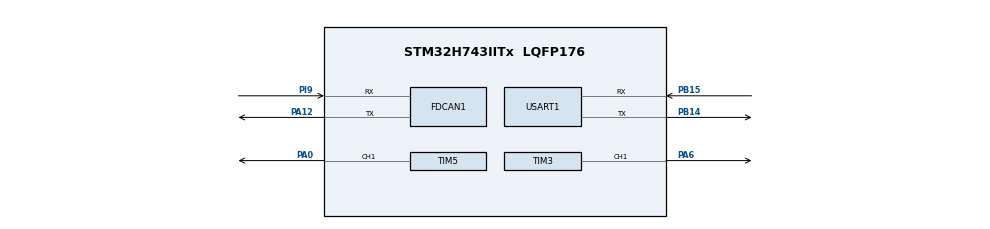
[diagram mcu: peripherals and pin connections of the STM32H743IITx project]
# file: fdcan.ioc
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CORTEX_M7.default_mode_Activation=1
FDCAN1.AutoRetransmission=ENABLE
FDCAN1.CalculateBaudRateNominal=416666
FDCAN1.CalculateTimeBitNominal=2400
FDCAN1.CalculateTimeQuantumNominal=800.0
FDCAN1.DataPrescaler=2
FDCAN1.DataTimeSeg1=7
FDCAN1.DataTimeSeg2=2
Mcu.Family=STM32H7
Mcu.Name=STM32H743IITx
Mcu.Package=LQFP176
NVIC.FDCAN1_IT0_IRQn=true\:0\:0\:false\:false\:true\:true\:true\:true
NVIC.FDCAN1_IT1_IRQn=true\:0\:0\:false\:false\:true\:true\:true\:true
NVIC.PriorityGroup=NVIC_PRIORITYGROUP_4
NVIC.USART1_IRQn=true\:0\:0\:false\:false\:true\:true\:true\:true
PA0.Signal=S_TIM5_CH1
PA12.Mode=FDCAN_Activate
PA12.Signal=FDCAN1_TX
PA6.Signal=S_TIM3_CH1
PB14.Mode=Asynchronous
PB14.Signal=USART1_TX
PB15.Mode=Asynchronous
PB15.Signal=USART1_RX
PH0-OSC_IN\ (PH0).Mode=HSE-External-Oscillator
PH0-OSC_IN\ (PH0).Signal=RCC_OSC_IN
PH1-OSC_OUT\ (PH1).Mode=HSE-External-Oscillator
PH1-OSC_OUT\ (PH1).Signal=RCC_OSC_OUT
PI9.Mode=FDCAN_Activate
PI9.Signal=FDCAN1_RX
ProjectManager.HeapSize=0x200
ProjectManager.StackSize=0x400
ProjectManager.TargetToolchain=MDK-ARM V5
RCC.ADCFreq_Value=400000000
RCC.APB1Freq_Value=100000000
RCC.APB2Freq_Value=50000000
RCC.APB3Freq_Value=100000000
RCC.APB4Freq_Value=100000000
RCC.CortexFreq_Value=100000000
RCC.D2PPRE2=RCC_APB2_DIV2
RCC.DIVM1=2
RCC.DIVM2=5
RCC.DIVM3=25
RCC.DIVN1=16
RCC.DIVN2=160
RCC.DIVN3=336
RCC.DIVQ1=10
RCC.HCLKFreq_Value=100000000
RCC.PLL2FRACN=0
RCC.PLL3FRACN=0
RCC.PLLFRACN=0
RCC.PLLSourceVirtual=RCC_PLLSOURCE_HSE
RCC.SYSCLKFreq_VALUE=100000000
RCC.SYSCLKSource=RCC_SYSCLKSOURCE_PLLCLK
RCC.USBFreq_Value=20000000
SH.S_TIM3_CH1.0=TIM3_CH1,Output Compare1 CH1
SH.S_TIM5_CH1.0=TIM5_CH1,PWM Generation1 CH1
STMicroelectronics.X-CUBE-ALGOBUILD.1.4.0.LibraryCcDSPOoLibraryJjDSPOoLibrary=true
TIM3.Channel-Output\ Compare1\ CH1=TIM_CHANNEL_1
TIM3.Period=999
TIM3.Pulse-Output\ Compare1\ CH1=500
TIM5.Channel-PWM\ Generation1\ CH1=TIM_CHANNEL_1
TIM5.Period=999
TIM5.Prescaler=239
USART1.VirtualMode-Asynchronous=VM_ASYNC
VP_MEMORYMAP_VS_MEMORYMAP.Mode=CurAppReg
VP_STMicroelectronics.X-CUBE-ALGOBUILD_VS_DSPOoLibraryJjLibrary_1.4.0_1.4.0.Mode=DSPOoLibraryJjLibrary
VP_TIM3_VS_ClockSourceINT.Mode=Internal
VP_TIM5_VS_ClockSourceINT.Mode=Internal
board=custom

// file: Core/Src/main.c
/* USER CODE BEGIN Header */
/**
  ******************************************************************************
  * @file           : main.c
  * @brief          : Main program body
  ******************************************************************************
  * @attention
  *
  * Copyright (c) 2025 STMicroelectronics.
  * All rights reserved.
  *
  * This software is licensed under terms that can be found in the LICENSE file
  * in the root directory of this software component.
  * If no LICENSE file comes with this software, it is provided AS-IS.
  *
  ******************************************************************************
  */
/* USER CODE END Header */
#include "main.h"
#include "fdcan.h"
#include "memorymap.h"
#include "tim.h"
#include "usart.h"
#include "gpio.h"

void SystemClock_Config(void);
static void MPU_Config(void);

int main(void)
{

  /* MPU Configuration--------------------------------------------------------*/
  MPU_Config();

  /* MCU Configuration--------------------------------------------------------*/

  /* Reset of all peripherals, Initializes the Flash interface and the Systick. */
  HAL_Init();

  /* Configure the system clock */
  SystemClock_Config();

  /* Initialize all configured peripherals */
  MX_GPIO_Init();
  MX_FDCAN1_Init();
  MX_TIM3_Init();
  MX_TIM5_Init();
  MX_USART1_UART_Init();
  /* USER CODE BEGIN 2 */
  HAL_TIM_Base_Start(&htim5);
  HAL_TIM_PWM_Start(&htim5, TIM_CHANNEL_1);
  HAL_TIM_PWM_Start(&htim5, TIM_CHANNEL_2);
  HAL_TIM_PWM_Start(&htim5, TIM_CHANNEL_3);
  __HAL_TIM_SetCompare(&htim5, TIM_CHANNEL_1, 0xffff);
  /* USER CODE END 2 */

  /* Infinite loop */
  while (1)
  {

  }
}

void SystemClock_Config(void)
{
  RCC_OscInitTypeDef RCC_OscInitStruct = {0};
  RCC_ClkInitTypeDef RCC_ClkInitStruct = {0};

  /** Supply configuration update enable
  */
  HAL_PWREx_ConfigSupply(PWR_LDO_SUPPLY);

  /** Configure the main internal regulator output voltage
  */
  __HAL_PWR_VOLTAGESCALING_CONFIG(PWR_REGULATOR_VOLTAGE_SCALE3);

  while(!__HAL_PWR_GET_FLAG(PWR_FLAG_VOSRDY)) {}

  /** Initializes the RCC Oscillators according to the specified parameters
  * in the RCC_OscInitTypeDef structure.
  */
  RCC_OscInitStruct.OscillatorType = RCC_OSCILLATORTYPE_HSE;
  RCC_OscInitStruct.HSEState = RCC_HSE_ON;
  RCC_OscInitStruct.PLL.PLLState = RCC_PLL_ON;
  RCC_OscInitStruct.PLL.PLLSource = RCC_PLLSOURCE_HSE;
  RCC_OscInitStruct.PLL.PLLM = 2;
  RCC_OscInitStruct.PLL.PLLN = 16;
  RCC_OscInitStruct.PLL.PLLP = 2;
  RCC_OscInitStruct.PLL.PLLQ = 10;
  RCC_OscInitStruct.PLL.PLLR = 2;
  RCC_OscInitStruct.PLL.PLLRGE = RCC_PLL1VCIRANGE_3;
  RCC_OscInitStruct.PLL.PLLVCOSEL = RCC_PLL1VCOWIDE;
  RCC_OscInitStruct.PLL.PLLFRACN = 0;
  if (HAL_RCC_OscConfig(&RCC_OscInitStruct) != HAL_OK)
  {
    Error_Handler();
  }

  /** Initializes the CPU, AHB and APB buses clocks
  */
  RCC_ClkInitStruct.ClockType = RCC_CLOCKTYPE_HCLK|RCC_CLOCKTYPE_SYSCLK
                              |RCC_CLOCKTYPE_PCLK1|RCC_CLOCKTYPE_PCLK2
                              |RCC_CLOCKTYPE_D3PCLK1|RCC_CLOCKTYPE_D1PCLK1;
  RCC_ClkInitStruct.SYSCLKSource = RCC_SYSCLKSOURCE_PLLCLK;
  RCC_ClkInitStruct.SYSCLKDivider = RCC_SYSCLK_DIV1;
  RCC_ClkInitStruct.AHBCLKDivider = RCC_HCLK_DIV1;
  RCC_ClkInitStruct.APB3CLKDivider = RCC_APB3_DIV1;
  RCC_ClkInitStruct.APB1CLKDivider = RCC_APB1_DIV1;
  RCC_ClkInitStruct.APB2CLKDivider = RCC_APB2_DIV2;
  RCC_ClkInitStruct.APB4CLKDivider = RCC_APB4_DIV1;

  if (HAL_RCC_ClockConfig(&RCC_ClkInitStruct, FLASH_LATENCY_2) != HAL_OK)
  {
    Error_Handler();
  }
}

 /* MPU Configuration */

void MPU_Config(void)
{
  MPU_Region_InitTypeDef MPU_InitStruct = {0};

  /* Disables the MPU */
  HAL_MPU_Disable();

  /** Initializes and configures the Region and the memory to be protected
  */
  MPU_InitStruct.Enable = MPU_REGION_ENABLE;
  MPU_InitStruct.Number = MPU_REGION_NUMBER0;
  MPU_InitStruct.BaseAddress = 0x0;
  MPU_InitStruct.Size = MPU_REGION_SIZE_4GB;
  MPU_InitStruct.SubRegionDisable = 0x87;
  MPU_InitStruct.TypeExtField = MPU_TEX_LEVEL0;
  MPU_InitStruct.AccessPermission = MPU_REGION_NO_ACCESS;
  MPU_InitStruct.DisableExec = MPU_INSTRUCTION_ACCESS_DISABLE;
  MPU_InitStruct.IsShareable = MPU_ACCESS_SHAREABLE;
  MPU_InitStruct.IsCacheable = MPU_ACCESS_NOT_CACHEABLE;
  MPU_InitStruct.IsBufferable = MPU_ACCESS_NOT_BUFFERABLE;

  HAL_MPU_ConfigRegion(&MPU_InitStruct);
  /* Enables the MPU */
  HAL_MPU_Enable(MPU_PRIVILEGED_DEFAULT);

}

void Error_Handler(void)
{
  __disable_irq();
  while (1)
  {
  }
}
